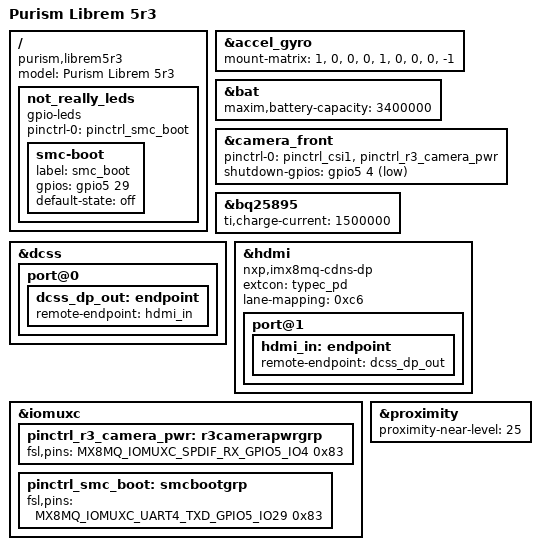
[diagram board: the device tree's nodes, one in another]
// SPDX-License-Identifier: (GPL-2.0+ OR MIT)
// Copyright (C) 2021 Purism SPC <kernel@puri.sm>

/dts-v1/;

/*
 * This file describes hardware that is shared among r3 ("Dogwood") and
 * later revisions of the Librem 5 so it has to be included there.
 */

#include "imx8mq-librem5.dtsi"

/ {
	model = "Purism Librem 5r3";
	compatible = "purism,librem5r3", "purism,librem5", "fsl,imx8mq";

	not_really_leds {
		compatible = "gpio-leds";
		pinctrl-names = "default";
		pinctrl-0 = <&pinctrl_smc_boot>;

		smc-boot {
			label = "smc_boot";
			gpios = <&gpio5 29 GPIO_ACTIVE_HIGH>;
			default-state = "off";
		};
	};
};

&accel_gyro {
	mount-matrix =  "1",  "0",  "0",
			"0",  "1",  "0",
			"0",  "0", "-1";
};

&bat {
	maxim,battery-capacity = <3400000>; /* uAh */
};

&camera_front {
	pinctrl-0 = <&pinctrl_csi1>, <&pinctrl_r3_camera_pwr>;
	shutdown-gpios = <&gpio5 4 GPIO_ACTIVE_LOW>;
};

&bq25895 {
	ti,charge-current = <1500000>; /* uA */
};

/delete-node/ &dcss_dsi_out;
/delete-node/ &mipi_dsi_dcss_in;
&dcss {
	status = "okay";

	port@0 {
		dcss_dp_out: endpoint {
			remote-endpoint = <&hdmi_in>;
		};
	};
};

&hdmi {
	compatible = "nxp,imx8mq-cdns-dp";
	extcon = <&typec_pd>;
	lane-mapping = <0xc6>;
	status = "okay";

	port@1 {
		hdmi_in: endpoint {
			remote-endpoint = <&dcss_dp_out>;
		};
	};
};

&iomuxc {
	pinctrl_r3_camera_pwr: r3camerapwrgrp {
		fsl,pins = <
			MX8MQ_IOMUXC_SPDIF_RX_GPIO5_IO4		0x83
		>;
	};

	pinctrl_smc_boot: smcbootgrp {
		 fsl,pins = <
			 /* SMC_BOOT0 */
			 MX8MQ_IOMUXC_UART4_TXD_GPIO5_IO29	0x83
		>;
	};
};

&proximity {
	proximity-near-level = <25>;
};
